# GD32A71x register map
File version: 1.0
CPU: CM7 r2p1, little endian, MPU, FPU, DSP, 4 interrupt priority bits
Registers are 32-bit, read-write, reset 0x0 unless marked. A register's access mark holds for its fields unless they carry their own. Offsets are from the block's base; [hi:lo] are bit positions.

## QSPI — Quad-SPI interface
Base 0x49001400
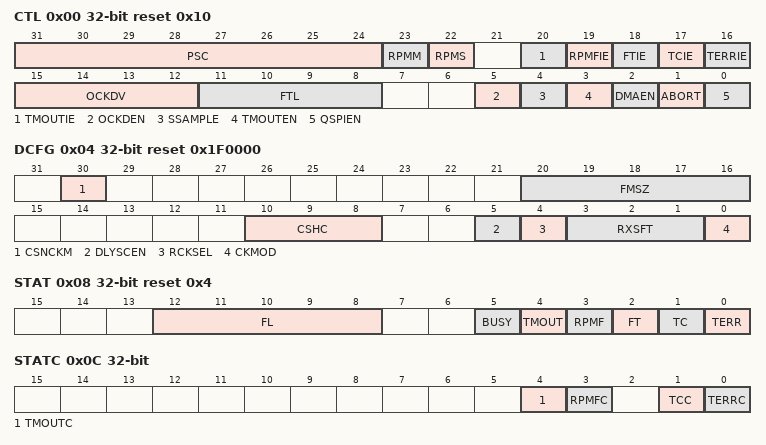
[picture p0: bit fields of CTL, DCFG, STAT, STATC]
0x00 CTL reset 0x10 — Control register
  [31:24] PSC — The clock prescaler of AHB clock for generating SCK
  [23] RPMM — Read polling match mode
  [22] RPMS — Read polling mode stop
  [20] TMOUTIE — Timeout interrupt enable
  [19] RPMFIE — Read polling mode match interrupt enable
  [18] FTIE — FIFO threshold interrupt enable
  [17] TCIE — Transfer complete interrupt enable
  [16] TERRIE — Transfer error interrupt enable
  [15:12] OCKDV — output clock delay value
  [11:8] FTL — FIFO threshold level
  [5] OCKDEN — Output clock delay enable when write data from flash
  [4] SSAMPLE — Sample delay
  [3] TMOUTEN — Timeout counter enable
  [2] DMAEN — DMA enable
  [1] ABORT — Abort request
  [0] QSPIEN — the QSPI enable
0x04 DCFG reset 0x1F0000 — Device configuration register
  [30] CSNCKM
  [20:16] FMSZ — Flash memory size
  [10:8] CSHC — Chip select high cycle
  [5] DLYSCEN — Delay scan enable
  [4] RCKSEL — Receive clock select
  [3:1] RXSFT — This bit indicates the SCK level when QSPI is free
  [0] CKMOD — This bit indicates the SCK level when QSPI is free
0x08 STAT access per field reset 0x4 — Status register
  [12:8] FL rw — FIFO level
  [5] BUSY ro — Busy flag
  [4] TMOUT ro — Timeout flag
  [3] RPMF ro — Read polling match flag
  [2] FT ro — FIFO threshold flag
  [1] TC ro — Transfer complete flag
  [0] TERR ro — Transfer error flag
0x0C STATC wo — Status clear register
  [4] TMOUTC — Clear timeout flag
  [3] RPMFC — Clear read polling mode match flag
  [1] TCC — Clear transfer complete flag
  [0] TERRC — Clear transfer error flag
0x10 DTLEN — Data length register
  [31:0] DTLEN — Data length
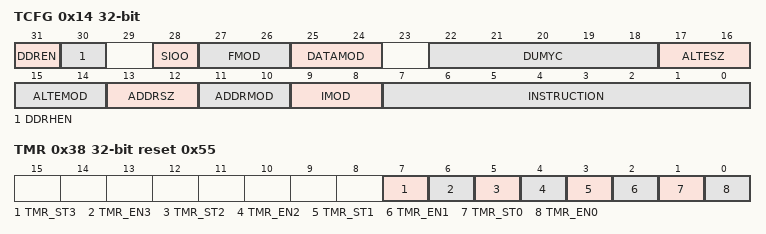
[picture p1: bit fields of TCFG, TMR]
0x14 TCFG — Transfer configuration register
  [31] DDREN — Double data rate mode enable
  [30] DDRHEN — DDR hold enable
  [28] SIOO — Send instruction only once mode
  [27:26] FMOD — Functional mode
  [25:24] DATAMOD — Data mode
  [22:18] DUMYC — Number of dummy cycles
  [17:16] ALTESZ — Alternate bytes size
  [15:14] ALTEMOD — Alternate bytes mode
  [13:12] ADDRSZ — Address size
  [11:10] ADDRMOD — Address mode
  [9:8] IMOD — Instruction mode
  [7:0] INSTRUCTION
0x18 ADDR — Address register
  [31:0] ADDR — Address to be send to the external Flash memory
0x1C ALTE — Alternate bytes register
  [31:0] ALTE — Alternate Bytes
0x20 DATA
  [31:0] DATA — Data that will be interacting with flash memory
0x24 STATMK — Status mask register
  [31:0] MASK — Status mask in read polling mode
0x28 STATMATCH — Status match register
  [31:0] MATCH — Status match in read polling mode
0x2C INTERVAL
  [15:0] INTERVAL — Interval cycle
0x30 TMOUT — Timeout register
  [15:0] TMOUTCYC — Timeout cycle
0x34 FLUSH wo — FIFO flush register
  [0] FLUSH — Used to flush all qspi interal fifo
0x38 TMR reset 0x55
  [7] TMR_ST3 — QSPI_FLUSH register TMR error status
  [6] TMR_EN3 — QSPI_FLUSH register TMR error output enable
  [5] TMR_ST2 — QSPI_TCFG register TMR error status
  [4] TMR_EN2 — QSPI_TCFG register TMR error output enable
  [3] TMR_ST1 — QSPI_DTLEN register TMR error status
  [2] TMR_EN1 — QSPI_DTLEN register TMR error output enable
  [1] TMR_ST0 — QSPI_CTL register TMR error status
  [0] TMR_EN0 — QSPI_CTL register TMR error output enable

## RTC — Real-time clock
Base 0x40002800
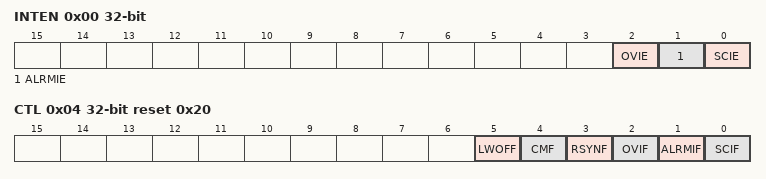
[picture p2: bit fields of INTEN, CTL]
0x00 INTEN — RTC interrupt enable register
  [2] OVIE — Overflow interrupt enable
  [1] ALRMIE — Alarm interrupt enable
  [0] SCIE — Second interrupt enable
0x04 CTL access per field reset 0x20 — RTC control register
  [5] LWOFF ro — Last write operation finished flag
  [4] CMF rw — Configuration mode flag
  [3] RSYNF rw — Registers synchronized flag
  [2] OVIF rw — Overflow interrupt flag
  [1] ALRMIF rw — Alarm interrupt flag
  [0] SCIF rw — Second interrupt flag
0x08 PSCH wo — RTC prescaler high register
  [3:0] PSC — RTC prescaler value high
0x0C PSCL wo reset 0x8000 — RTC prescaler low register
  [15:0] PSC — RTC prescaler value low
0x10 DIVH ro — RTC divider high register
  [3:0] DIV — RTC divider value high
0x14 DIVL ro reset 0x8000 — RTC divider low register
  [15:0] DIV — RTC divider value low
0x18 CNTH — RTC counter high register
  [15:0] CNT — RTC counter value high
0x1C CNTL — RTC counter low register
  [15:0] CNT — RTC counter value low
0x20 ALRMH wo reset 0xFFFF — RTC alarm high register
  [15:0] ALRM — RTC alarm value high
0x24 ALRML wo reset 0xFFFF — RTC alarm low register
  [15:0] ALRM — RTC alarm value low
